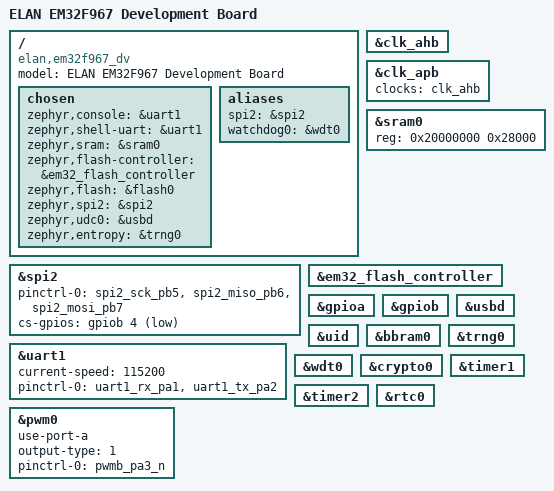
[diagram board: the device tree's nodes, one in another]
/*
 * Copyright (c) 2024 ELAN Microelectronics Corp.
 * SPDX-License-Identifier: Apache-2.0
 */

/dts-v1/;

#include <arm/armv7-m.dtsi>
#include <elan/em32fxxx.dtsi>
#include <elan/em32f967-pinctrl.dtsi>
#include <zephyr/dt-bindings/input/input-event-codes.h>

/ {
	model = "ELAN EM32F967 Development Board";
	compatible = "elan,em32f967_dv";

	chosen {
		zephyr,console = &uart1;
		zephyr,shell-uart = &uart1;
		zephyr,sram = &sram0;
		zephyr,flash-controller = &em32_flash_controller;
		zephyr,flash = &flash0;
		zephyr,spi2 = &spi2;
		zephyr,udc0 = &usbd;
		zephyr,entropy = &trng0;
	};

	aliases {
		spi2 = &spi2;
		watchdog0 = &wdt0;
	};
};

&clk_ahb {
	status = "okay";
};

&clk_apb {
	clocks = <&clk_ahb>;
	status = "okay";
};

&sram0 {
	reg = <0x20000000 0x28000>;
};

&spi2 {
	status = "okay";
	pinctrl-0 = <&spi2_sck_pb5 &spi2_miso_pb6 &spi2_mosi_pb7>;
	pinctrl-names = "default";
	cs-gpios = <&gpiob 4 GPIO_ACTIVE_LOW>;
};

&uart1 {
	status = "okay";
	current-speed = <115200>;
	pinctrl-0 = <&uart1_rx_pa1 &uart1_tx_pa2>;
	pinctrl-names = "default";
};

&em32_flash_controller {
	status = "okay";
};

&gpioa {
	status = "okay";
};

&gpiob {
	status = "okay";
};

zephyr_udc0: &usbd {
	status = "okay";
};

&uid {
	status = "okay";
};

&bbram0 {
	status = "okay";
};

&trng0 {
	status = "okay";
};

&wdt0 {
	status = "okay";
};

&crypto0 {
	status = "okay";
};

/* Enable Timer controllers */
&timer1 {
	status = "okay";
};

&timer2 {
	status = "okay";
};

/* Enable RTC */
&rtc0 {
	status = "okay";
};

/* Enable PWM Controller - PWMB N output on PA3 */
&pwm0 {
	status = "okay";
	use-port-a;			/* Use Port A pins (PWM_S=0) */
	output-type = <1>;		/* N output only */
	pinctrl-0 = <&pwmb_pa3_n>;
	pinctrl-names = "default";
};
